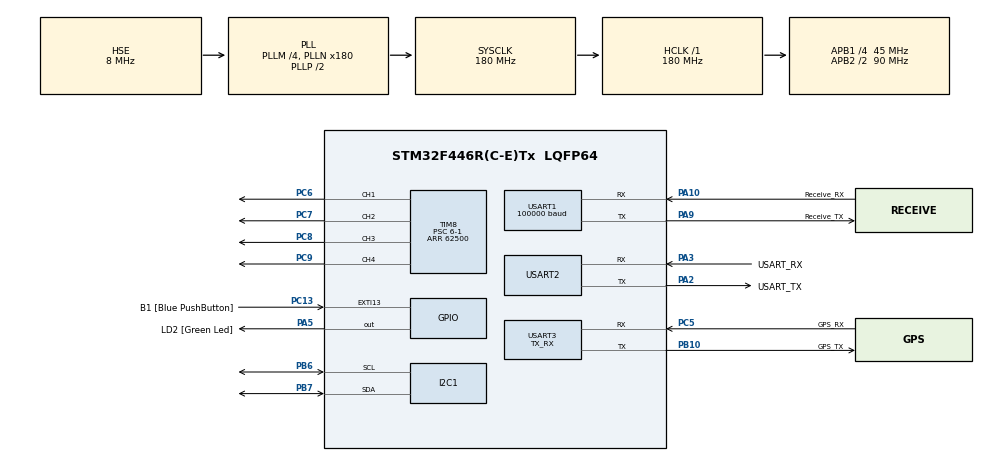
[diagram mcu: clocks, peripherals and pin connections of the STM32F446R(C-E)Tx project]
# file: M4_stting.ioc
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I2C1.I2C_Mode=I2C_Fast
Mcu.Family=STM32F4
Mcu.Name=STM32F446R(C-E)Tx
Mcu.Package=LQFP64
NVIC.PriorityGroup=NVIC_PRIORITYGROUP_0
NVIC.USART1_IRQn=true\:0\:0\:false\:false\:true\:true
NVIC.USART3_IRQn=true\:0\:0\:false\:false\:true\:true
PA10.GPIO_Label=Receive_RX
PA10.Mode=Asynchronous
PA10.Signal=USART1_RX
PA13.GPIO_Label=TMS
PA13.Mode=Serial_Wire
PA13.Signal=SYS_JTMS-SWDIO
PA14.GPIO_Label=TCK
PA14.Mode=Serial_Wire
PA14.Signal=SYS_JTCK-SWCLK
PA2.GPIO_Label=USART_TX
PA2.Mode=Asynchronous
PA2.Signal=USART2_TX
PA3.GPIO_Label=USART_RX
PA3.Mode=Asynchronous
PA3.Signal=USART2_RX
PA5.GPIO_Label=LD2 [Green Led]
PA5.Signal=GPIO_Output
PA9.GPIO_Label=Receive_TX
PA9.Mode=Asynchronous
PA9.Signal=USART1_TX
PB10.GPIO_Label=GPS_TX
PB10.Mode=Asynchronous
PB10.Signal=USART3_TX
PB3.GPIO_Label=SWO
PB3.Signal=SYS_JTDO-SWO
PB6.Mode=I2C
PB6.Signal=I2C1_SCL
PB7.Mode=I2C
PB7.Signal=I2C1_SDA
PC13.GPIO_Label=B1 [Blue PushButton]
PC13.GPIO_ModeDefaultEXTI=GPIO_MODE_IT_FALLING
PC13.Signal=GPXTI13
PC14-OSC32_IN.Mode=LSE-External-Oscillator
PC14-OSC32_IN.Signal=RCC_OSC32_IN
PC15-OSC32_OUT.Mode=LSE-External-Oscillator
PC15-OSC32_OUT.Signal=RCC_OSC32_OUT
PC5.GPIO_Label=GPS_RX
PC5.Mode=Asynchronous
PC5.Signal=USART3_RX
PC6.Signal=S_TIM8_CH1
PC7.Signal=S_TIM8_CH2
PC8.Signal=S_TIM8_CH3
PC9.Signal=S_TIM8_CH4
PH0-OSC_IN.Mode=HSE-External-Clock-Source
PH0-OSC_IN.Signal=RCC_OSC_IN
PH1-OSC_OUT.Mode=HSE-External-Clock-Source
PH1-OSC_OUT.Signal=RCC_OSC_OUT
ProjectManager.HeapSize=0x200
ProjectManager.StackSize=0x400
ProjectManager.TargetToolchain=TrueSTUDIO
RCC.48MHZClocksFreq_Value=84000000
RCC.AHBFreq_Value=180000000
RCC.APB1CLKDivider=RCC_HCLK_DIV4
RCC.APB1Freq_Value=45000000
RCC.APB1TimFreq_Value=90000000
RCC.APB2CLKDivider=RCC_HCLK_DIV2
RCC.APB2Freq_Value=90000000
RCC.APB2TimFreq_Value=180000000
RCC.CortexFreq_Value=180000000
RCC.FLatency-AdvancedSettings=FLASH_LATENCY_5
RCC.HCLKFreq_Value=180000000
RCC.HSE_VALUE=8000000
RCC.HSI_VALUE=16000000
RCC.PLLM=4
RCC.PLLN=180
RCC.PLLSourceVirtual=RCC_PLLSOURCE_HSE
RCC.SYSCLKFreq_VALUE=180000000
RCC.SYSCLKSource=RCC_SYSCLKSOURCE_PLLCLK
RCC.USBFreq_Value=180000000
RCC.VCOOutputFreq_Value=360000000
SH.S_TIM8_CH1.0=TIM8_CH1,PWM Generation1 CH1
SH.S_TIM8_CH2.0=TIM8_CH2,PWM Generation2 CH2
SH.S_TIM8_CH3.0=TIM8_CH3,PWM Generation3 CH3
SH.S_TIM8_CH4.0=TIM8_CH4,PWM Generation4 CH4
TIM10.Period=10000
TIM10.Prescaler=18000
TIM8.Channel-PWM\ Generation1\ CH1=TIM_CHANNEL_1
TIM8.Channel-PWM\ Generation2\ CH2=TIM_CHANNEL_2
TIM8.Channel-PWM\ Generation3\ CH3=TIM_CHANNEL_3
TIM8.Channel-PWM\ Generation4\ CH4=TIM_CHANNEL_4
TIM8.OCMode_PWM-PWM\ Generation4\ CH4=TIM_OCMODE_PWM1
TIM8.Period=62500
TIM8.Prescaler=6-1
USART1.BaudRate=100000
USART1.Mode=MODE_RX
USART1.Parity=PARITY_EVEN
USART1.StopBits=STOPBITS_2
USART1.VirtualMode=VM_ASYNC
USART1.WordLength=WORDLENGTH_9B
USART2.VirtualMode=VM_ASYNC
USART3.Mode=MODE_TX_RX
USART3.VirtualMode=VM_ASYNC
VP_TIM10_VS_ClockSourceINT.Mode=Enable_Timer
VP_TIM8_VS_ClockSourceINT.Mode=Internal
board=NUCLEO-F446RE

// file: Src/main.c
/**
  ******************************************************************************
  * @file           : main.c
  * @brief          : Main program body
  ******************************************************************************
  ** This notice applies to any and all portions of this file
  * that are not between comment pairs USER CODE BEGIN and
  * USER CODE END. Other portions of this file, whether
  * inserted by the user or by software development tools
  * are owned by their respective copyright owners.
  *
  * COPYRIGHT(c) 2019 STMicroelectronics
  *
  * Redistribution and use in source and binary forms, with or without modification,
  * are permitted provided that the following conditions are met:
  *   1. Redistributions of source code must retain the above copyright notice,
  *      this list of conditions and the following disclaimer.
  *   2. Redistributions in binary form must reproduce the above copyright notice,
  *      this list of conditions and the following disclaimer in the documentation
  *      and/or other materials provided with the distribution.
  *   3. Neither the name of STMicroelectronics nor the names of its contributors
  *      may be used to endorse or promote products derived from this software
  *      without specific prior written permission.
  *
  * THIS SOFTWARE IS PROVIDED BY THE COPYRIGHT HOLDERS AND CONTRIBUTORS "AS IS"
  * AND ANY EXPRESS OR IMPLIED WARRANTIES, INCLUDING, BUT NOT LIMITED TO, THE
  * IMPLIED WARRANTIES OF MERCHANTABILITY AND FITNESS FOR A PARTICULAR PURPOSE ARE
  * DISCLAIMED. IN NO EVENT SHALL THE COPYRIGHT HOLDER OR CONTRIBUTORS BE LIABLE
  * FOR ANY DIRECT, INDIRECT, INCIDENTAL, SPECIAL, EXEMPLARY, OR CONSEQUENTIAL
  * DAMAGES (INCLUDING, BUT NOT LIMITED TO, PROCUREMENT OF SUBSTITUTE GOODS OR
  * SERVICES; LOSS OF USE, DATA, OR PROFITS; OR BUSINESS INTERRUPTION) HOWEVER
  * CAUSED AND ON ANY THEORY OF LIABILITY, WHETHER IN CONTRACT, STRICT LIABILITY,
  * OR TORT (INCLUDING NEGLIGENCE OR OTHERWISE) ARISING IN ANY WAY OUT OF THE USE
  * OF THIS SOFTWARE, EVEN IF ADVISED OF THE POSSIBILITY OF SUCH DAMAGE.
  *
  ******************************************************************************
  */
#include "main.h"
#include "stm32f4xx_hal.h"
#include "i2c.h"
#include "tim.h"
#include "usart.h"
#include "gpio.h"

/* USER CODE BEGIN Includes */
#include "My_Inc/my_Control_lib.h"

/* USER CODE END Includes */

/* USER CODE BEGIN PV */
/* Private variables ---------------------------------------------------------*/

/* USER CODE END PV */

void SystemClock_Config(void);

/* USER CODE BEGIN PFP */
/* Private function prototypes -----------------------------------------------*/

/* USER CODE END PFP */

int main(void)
{

  /* MCU Configuration----------------------------------------------------------*/

  /* Reset of all peripherals, Initializes the Flash interface and the Systick. */
  HAL_Init();

  /* Configure the system clock */
  SystemClock_Config();

  /* Initialize all configured peripherals */
  MX_GPIO_Init();
  MX_USART2_UART_Init();
  MX_USART3_UART_Init();
  MX_USART1_UART_Init();
  MX_I2C1_Init();
  MX_TIM8_Init();
  MX_TIM10_Init();
  /* USER CODE BEGIN 2 */
  Total_Init();
	//Motor PWM Init
	//Motor_init();

	//RxInterupt Set
	//usart_DMA_init();

  HAL_TIM_Base_Start_IT(&htim10);
  //HAL_TIM_PWM_Start(&htim8,TIM_CHANNEL_ALL);
  /* USER CODE END 2 */

  /* Infinite loop */
  while (1)
  {

  /* USER CODE BEGIN 3 */

	  //calibration_Loop();
	  stabilizer_Loop();

  }
  /* USER CODE END 3 */

}

void SystemClock_Config(void)
{

  RCC_OscInitTypeDef RCC_OscInitStruct;
  RCC_ClkInitTypeDef RCC_ClkInitStruct;

    /**Configure the main internal regulator output voltage
    */
  __HAL_RCC_PWR_CLK_ENABLE();

  __HAL_PWR_VOLTAGESCALING_CONFIG(PWR_REGULATOR_VOLTAGE_SCALE1);

    /**Initializes the CPU, AHB and APB busses clocks
    */
  RCC_OscInitStruct.OscillatorType = RCC_OSCILLATORTYPE_HSE;
  RCC_OscInitStruct.HSEState = RCC_HSE_BYPASS;
  RCC_OscInitStruct.PLL.PLLState = RCC_PLL_ON;
  RCC_OscInitStruct.PLL.PLLSource = RCC_PLLSOURCE_HSE;
  RCC_OscInitStruct.PLL.PLLM = 4;
  RCC_OscInitStruct.PLL.PLLN = 180;
  RCC_OscInitStruct.PLL.PLLP = RCC_PLLP_DIV2;
  RCC_OscInitStruct.PLL.PLLQ = 2;
  RCC_OscInitStruct.PLL.PLLR = 2;
  if (HAL_RCC_OscConfig(&RCC_OscInitStruct) != HAL_OK)
  {
    _Error_Handler(__FILE__, __LINE__);
  }

    /**Activate the Over-Drive mode
    */
  if (HAL_PWREx_EnableOverDrive() != HAL_OK)
  {
    _Error_Handler(__FILE__, __LINE__);
  }

    /**Initializes the CPU, AHB and APB busses clocks
    */
  RCC_ClkInitStruct.ClockType = RCC_CLOCKTYPE_HCLK|RCC_CLOCKTYPE_SYSCLK
                              |RCC_CLOCKTYPE_PCLK1|RCC_CLOCKTYPE_PCLK2;
  RCC_ClkInitStruct.SYSCLKSource = RCC_SYSCLKSOURCE_PLLCLK;
  RCC_ClkInitStruct.AHBCLKDivider = RCC_SYSCLK_DIV1;
  RCC_ClkInitStruct.APB1CLKDivider = RCC_HCLK_DIV4;
  RCC_ClkInitStruct.APB2CLKDivider = RCC_HCLK_DIV2;

  if (HAL_RCC_ClockConfig(&RCC_ClkInitStruct, FLASH_LATENCY_5) != HAL_OK)
  {
    _Error_Handler(__FILE__, __LINE__);
  }

    /**Configure the Systick interrupt time
    */
  HAL_SYSTICK_Config(HAL_RCC_GetHCLKFreq()/1000);

    /**Configure the Systick
    */
  HAL_SYSTICK_CLKSourceConfig(SYSTICK_CLKSOURCE_HCLK);

  /* SysTick_IRQn interrupt configuration */
  HAL_NVIC_SetPriority(SysTick_IRQn, 0, 0);
}

void _Error_Handler(char *file, int line)
{
  while(1)
  {
  }
}

/************************ (C) COPYRIGHT STMicroelectronics *****END OF FILE****/
